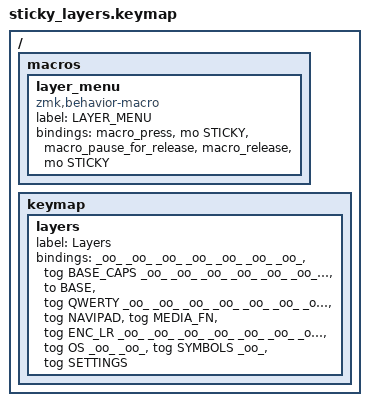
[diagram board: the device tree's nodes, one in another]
/ {
    macros {
		layer_menu: layer_menu {
			compatible = "zmk,behavior-macro";
			label = "LAYER_MENU";
			#binding-cells = <0>;
			bindings =
				<&macro_press>,
				<&mo STICKY>,
				<&macro_pause_for_release>,
				<&macro_release>,
				<&mo STICKY>;
		};
	};
    keymap {
        layers {
			label = "Layers";
			bindings = <
//                ┌──────┬──────┬──────┬──────┬──────┬──────┐                                                    ┌─────────────┬───────────────┬──────────────┬──────┬──────┬──────┐
//                │ _oo_ │ _oo_ │ _oo_ │ _oo_ │ _oo_ │ _oo_ │                                                    │    _oo_     │ tog BASE_CAPS │     _oo_     │ _oo_ │ _oo_ │ _oo_ │
//                ├──────┼──────┼──────┼──────┼──────┼──────┤                                                    ├─────────────┼───────────────┼──────────────┼──────┼──────┼──────┤
//                │ _oo_ │ _oo_ │ _oo_ │ _oo_ │ _oo_ │ _oo_ │                                                    │   to BASE   │  tog QWERTY   │     _oo_     │ _oo_ │ _oo_ │ _oo_ │
//                ├──────┼──────┼──────┼──────┼──────┼──────┼─────────────┬──────────────┐   ┌────────────┬──────┼─────────────┼───────────────┼──────────────┼──────┼──────┼──────┤
//                │ _oo_ │ _oo_ │ _oo_ │ _oo_ │ _oo_ │ _oo_ │ tog NAVIPAD │ tog MEDIA_FN │   │ tog ENC_LR │ _oo_ │    _oo_     │     _oo_      │     _oo_     │ _oo_ │ _oo_ │ _oo_ │
//                └──────┴──────┴──────┼──────┼──────┼──────┼─────────────┼──────────────┤   ├────────────┼──────┼─────────────┼───────────────┼──────────────┼──────┴──────┴──────┘
//                                     │ _oo_ │ _oo_ │ _oo_ │    _oo_     │    tog OS    │   │    _oo_    │ _oo_ │ tog SYMBOLS │     _oo_      │ tog SETTINGS │                     
//                                     └──────┴──────┴──────┴─────────────┴──────────────┘   └────────────┴──────┴─────────────┴───────────────┴──────────────┘                     
              _oo_   _oo_   _oo_   _oo_   _oo_   _oo_                                                           _oo_           &tog BASE_CAPS   _oo_            _oo_   _oo_   _oo_
              _oo_   _oo_   _oo_   _oo_   _oo_   _oo_                                                           &to BASE       &tog QWERTY      _oo_            _oo_   _oo_   _oo_
              _oo_   _oo_   _oo_   _oo_   _oo_   _oo_   &tog NAVIPAD   &tog MEDIA_FN       &tog ENC_LR   _oo_   _oo_           _oo_             _oo_            _oo_   _oo_   _oo_
                                   _oo_   _oo_   _oo_   _oo_           &tog OS             _oo_          _oo_   &tog SYMBOLS   _oo_             &tog SETTINGS                     
            >;
		};

    };
};
